# TESTDEV register map
File version: 1.0
Synthetic device for gen_svd_regs.py tests
Registers are 32-bit, read-write, reset 0xAA unless marked. A register's access mark holds for its fields unless they carry their own. Offsets are from the block's base; lines under a group give offsets from that group; [hi:lo] are bit positions; {n}, {i} and the like mark numbered series; 'fields as' and 'values as' point back to an identical list; <NAME> marks a mode.

## Memory map
0x40000000 TESTA size 0x100 — Covers the register-level rules
0x50000000 TESTB size 0x100

## Interrupts
5 TESTA_IRQ (TESTA)
9 TESTB_EVT (TESTB)

## TESTA — Covers the register-level rules
Base 0x40000000
Same registers: TESTB 0x50000000
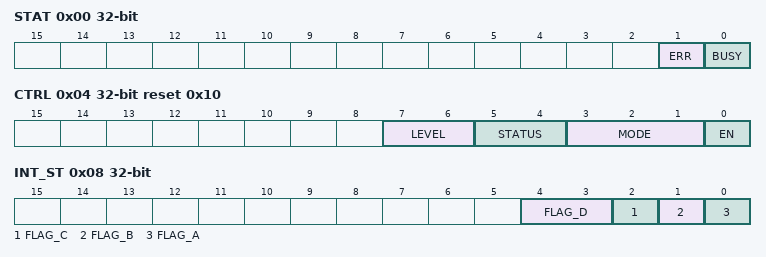
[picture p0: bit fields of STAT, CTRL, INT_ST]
0x00 STAT ro
  [1] ERR rw, [0] BUSY
0x04 CTRL reset 0x10
  [7:6] LEVEL, [5:4] STATUS ro, [3:1] MODE wo, [0] EN
0x08 INT_ST
  [4:3] FLAG_D write-1-clears, [2] FLAG_C read-clears, [1] FLAG_B write-1-sets, [0] FLAG_A write-1-clears
0x0C RC_REG reset 0x0 read-clears
0x10 BYTE 8-bit reset 0xA5
  [3:0] LOW ro
0x20 DATA_A reset 0x11
0x20 DATA_B (alternate view of DATA_A)
{0x40+0x10*i} CH[{i}] (i=0..2) group — Channel block
  0x00 CFG ro reset 0x5
  0x04 CNT reset 0x0

## Notices in the file
SPDX-License-Identifier: PolyForm-Noncommercial-1.0.0
Copyright (c) 2026 Alex Kaplan
